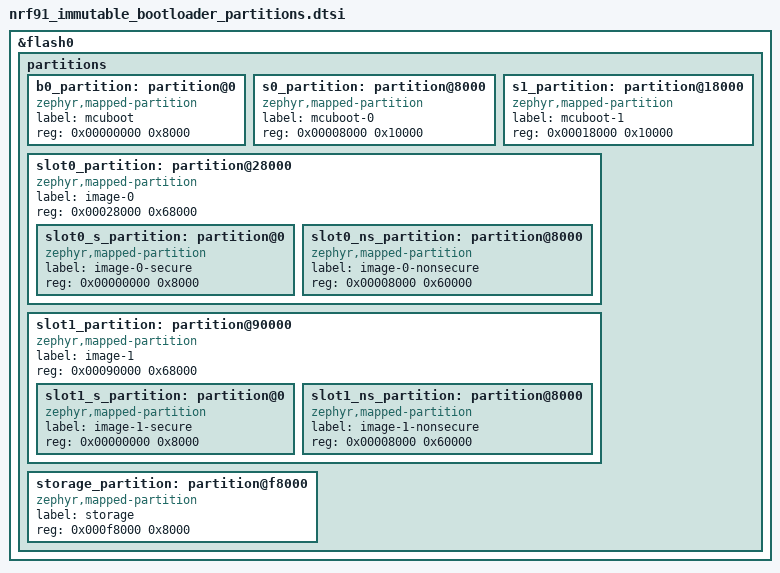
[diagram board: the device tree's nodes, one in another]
/*
 * Copyright (c) 2026 Nordic Semiconductor
 * SPDX-License-Identifier: LicenseRef-Nordic-5-Clause
 */

/delete-node/ &boot_partition;
/delete-node/ &slot0_partition;
/delete-node/ &slot1_partition;
/delete-node/ &tfm_ps_partition;
/delete-node/ &tfm_its_partition;
/delete-node/ &tfm_otp_partition;
/delete-node/ &storage_partition;

&flash0 {
	/*
	 * 0x0000_0000  B0 (NSIB)                    ( 32 kB)
	 * 0x0000_8000  Primary updatable MCUboot    ( 64 kB)
	 * 0x0001_8000  Secondary updatable MCUboot  ( 64 kB)
	 * 0x0002_8000  Primary image area           (416 kB)
	 *   0x0002_8000  Primary secure image       ( 32 kB)
	 *   0x0003_0000  Primary non-secure image   (384 kB)
	 * 0x0009_0000  Secondary image area         (416 kB)
	 *   0x0009_0000  Secondary secure image     ( 32 kB)
	 *   0x0009_8000  Secondary non-secure image (384 kB)
	 * 0x000f_8000  Settings storage             ( 32 kB)
	 */

	partitions {
		ranges;
		#address-cells = <1>;
		#size-cells = <1>;

		b0_partition: partition@0 {
			compatible = "zephyr,mapped-partition";
			label = "mcuboot";
			reg = <0x00000000 0x8000>;
		};

		s0_partition: partition@8000 {
			compatible = "zephyr,mapped-partition";
			label = "mcuboot-0";
			reg = <0x00008000 0x10000>;
		};

		s1_partition: partition@18000 {
			compatible = "zephyr,mapped-partition";
			label = "mcuboot-1";
			reg = <0x00018000 0x10000>;
		};

		slot0_partition: partition@28000 {
			compatible = "zephyr,mapped-partition";
			label = "image-0";
			reg = <0x00028000 0x68000>;
			ranges = <0x0 0x00028000 0x68000>;
			#address-cells = <1>;
			#size-cells = <1>;

			slot0_s_partition: partition@0 {
				compatible = "zephyr,mapped-partition";
				label = "image-0-secure";
				reg = <0x00000000 0x8000>;
			};

			slot0_ns_partition: partition@8000 {
				compatible = "zephyr,mapped-partition";
				label = "image-0-nonsecure";
				reg = <0x00008000 0x60000>;
			};
		};

		slot1_partition: partition@90000 {
			compatible = "zephyr,mapped-partition";
			label = "image-1";
			reg = <0x00090000 0x68000>;
			ranges = <0x0 0x00090000 0x68000>;
			#address-cells = <1>;
			#size-cells = <1>;

			slot1_s_partition: partition@0 {
				compatible = "zephyr,mapped-partition";
				label = "image-1-secure";
				reg = <0x00000000 0x8000>;
			};

			slot1_ns_partition: partition@8000 {
				compatible = "zephyr,mapped-partition";
				label = "image-1-nonsecure";
				reg = <0x00008000 0x60000>;
			};
		};

		storage_partition: partition@f8000 {
			compatible = "zephyr,mapped-partition";
			label = "storage";
			reg = <0x000f8000 0x8000>;
		};
	};
};
